# ISP_CBUFF register map
Vendor: Texas Instruments
Peripheral module from a debugger description file (folder omap36xx).
Registers are 32-bit, read-write, reset 0x0 unless marked. A register's access mark holds for its fields unless they carry their own. Offsets are as the file gives them; lines under a group give offsets from that group; [hi:lo] are bit positions; {n}, {i} and the like mark numbered series; 'fields as' and 'values as' point back to an identical list; <NAME> marks a mode.

## ISP_CBUFF
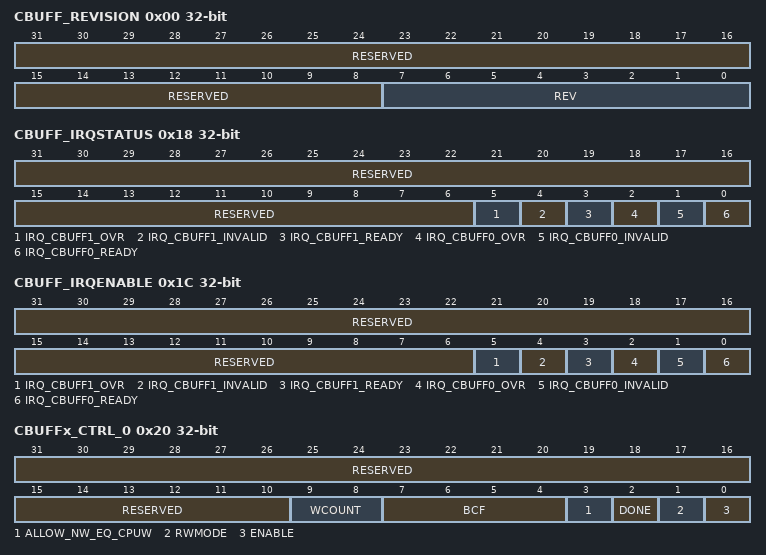
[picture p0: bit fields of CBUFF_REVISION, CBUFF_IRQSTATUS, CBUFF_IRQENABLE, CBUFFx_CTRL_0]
0x00 CBUFF_REVISION ro (reset mask 0xFFFFFF00) — This register contains the IP revision code
  [31:8] RESERVED — Write 0s for future compatibility. Read returns 0.
  [7:0] REV — IP revision[7:4] Major revision . [3:0] Minor revision .
0x10 CBUFF_SYSCONFIG — This register allows controlling various parameters of the Interconnect interface.
  [31:0] RESERVED — Write 0s for future compatibility. Reads return zero.
0x14 CBUFF_SYSSTATUS ro — The register provides status information about the module, excluding the interrupt status information
0x18 CBUFF_IRQSTATUS access not given — The interrupt status register regroups all the status of the module internal events that can generate an interrupt.
  [31:6] RESERVED rw — Write 0s for future compatibility. Reads return zero.
  [5] IRQ_CBUFF1_OVR — Buffer overflow event. (access R/W/1toClr)
    0=No done interrupt pending (r); Status unchanged (w); 1=Done interrupt pending (r); Status bit cleared (w)
  [4] IRQ_CBUFF1_INVALID — Invalid access. (access R/W/1toClr)
    values as IRQ_CBUFF1_OVR
  [3] IRQ_CBUFF1_READY — The CPUW1 physical buffer is ready to be accessed by the CPU. (access R/W/1toClr)
    values as IRQ_CBUFF1_OVR
  [2] IRQ_CBUFF0_OVR — Buffer overflow event. (access R/W/1toClr)
    values as IRQ_CBUFF1_OVR
  [1] IRQ_CBUFF0_INVALID — Invalid access. (access R/W/1toClr)
    0=No YUV buffer done interrupt pending (r); Status unchanged (w); 1=YUV buffer done interrupt pending (r); Status bit cleared (w)
  [0] IRQ_CBUFF0_READY — The CPUW0 physical buffer is ready to be accessed by the CPU. (access R/W/1toClr)
    values as IRQ_CBUFF1_OVR
0x1C CBUFF_IRQENABLE — The interrupt enable register allows to enable/disable the module internal sources of interrupt, on an event-by-event basis.
  [31:6] RESERVED — Write 0s for future compatibility. Reads return zero.
  [5] IRQ_CBUFF1_OVR — Buffer overflow event.
    0=interrupt is masked; 1=Interrupt is enabled
  [4] IRQ_CBUFF1_INVALID — Invalid access.
    0=interrupt is masked; 1=Interrupt is enabled
  [3] IRQ_CBUFF1_READY — The CPUW1 physical buffer is ready to be accessed by the CPU.
    0=interrupt is masked; 1=Interrupt is enabled
  [2] IRQ_CBUFF0_OVR — Buffer overflow event.
    0=interrupt is masked; 1=Interrupt is enabled
  [1] IRQ_CBUFF0_INVALID — Invalid access.
    0=interrupt is masked; 1=Interrupt is enabled
  [0] IRQ_CBUFF0_READY — The CPUW0 physical buffer is ready to be accessed by the CPU.
    0=interrupt is masked; 1=Interrupt is enabled
0x20 CBUFFx_CTRL_0 access per field — Circular buffer x control register
  [31:10] RESERVED rw — Write 0s for future compatibility.Reads returns 0.
  [9:8] WCOUNT rw — Window count
    0=2 windows; 1=4 windows; 2=8 windows; 3=16 windows
  [7:4] BCF rw — This register controls the bandwidth control feedback loop output.Functionality depends on subsystem integration.0: Control loop disabled. Data read from memory is free running.1-15: The control feedback loop signal is asserted when the window count available for ISP is below () the threshold.In other words at least (=) BCF windows are available for ISP access when this signal is released.
  [3] ALLOW_NW_EQ_CPUW rw — Allow NW=CPUW. Better buffer utilization when ISP does not use the next write window.
    0=When the CPUW and the NW pointers designate the same window and accesses are effectively performed to those windows an overflow event occurs.This happens when - the CPU has received an READY IRQ for that window indicating that it can be accessed and - the ISP performs an access to that window. ISP accesses are tracked based on OCPI activity.; 1=When the CPUW and the CW pointers designate the same window and accesses are effectively performed to those windows an overflow event occurs.This happens when - the CPU has received an READY IRQ for that window indicating that it can be accessed and - the ISP performs an access to that window. ISP accesses are tracked based on OCPI activity.
  [2] DONE wo — Write this bit to 1 to indicate the CPU has finished processing its physical buffer.This bit is automatically cleared by hardware, reads always return 0.
    0=No effect; 1=The CPU has completely processed the CPUW physical buffer
  [1] RWMODE rw — Selects read or write mode
    0=Write mode. HW writes and CPU reads the physical space. CPU accesses are out of CBUFF module's scope, therefore only writes are permitted between CBUFF0_START and CBUFF0_END.; 1=Read mode. HW reads and CPU writes the physical space. CPU accesses are out of CBUFF module's scope; therefore only reads are permitted between CBUFF0_START and CBUFF0_END.
  [0] ENABLE rw — Enable/disable
    0=Disables the circular buffer 0; this resets the internal state of circular buffer 0. All accesses received on OCPI are transmitted to OCPO without modification. Disabling the module takes effect immediately. It is SW responsibility to ensure that no more accesses to CBUFF0 are outstanding before disabling the module. Otherwise memory corruption may occur.; 1=Enable the circular buffer 0. All accesses between CBUFF0_START and CBUFF0_END are processed by the module.
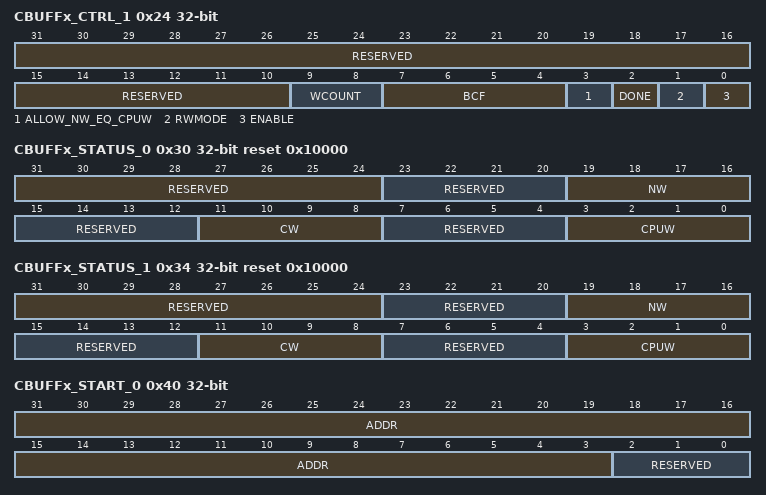
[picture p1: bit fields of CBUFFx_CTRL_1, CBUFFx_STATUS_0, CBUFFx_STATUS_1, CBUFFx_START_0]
0x24 CBUFFx_CTRL_1 access per field — Circular buffer x control register
  fields as CBUFFx_CTRL_0
0x30 CBUFFx_STATUS_0 ro reset 0x10000 — Threshold value used to check if the CW or NW windows are full.
  [31:24] RESERVED — Write 0s for future compatibility. Read returns 0.
  [23:20] RESERVED — Write 0s for future compatibility. Read returns 0.
  [19:16] NW — Next window number.Valid values depend on the CBUFF_CTRL.WCOUNT register.
  [15:12] RESERVED — Write 0s for future compatibility. Read returns 0.
  [11:8] CW — Current window number.Valid values depend on the CBUFF_CTRL.WCOUNT register.
  [7:4] RESERVED — Write 0s for future compatibility. Read returns 0.
  [3:0] CPUW — Current CPU window number.Valid values depend on the CBUFF_CTRL.WCOUNT register.
0x34 CBUFFx_STATUS_1 ro reset 0x10000 — Threshold value used to check if the CW or NW windows are full.
  fields as CBUFFx_STATUS_0
0x40 CBUFFx_START_0 — Start address of the virtual space managed by circular buffer x. Start address of the 1st physical buffer managed by circular buffer x.
  [31:3] ADDR — Address, in 64 bit words.
  [2:0] RESERVED — Write 0s for future compatibility.Reads returns 0.
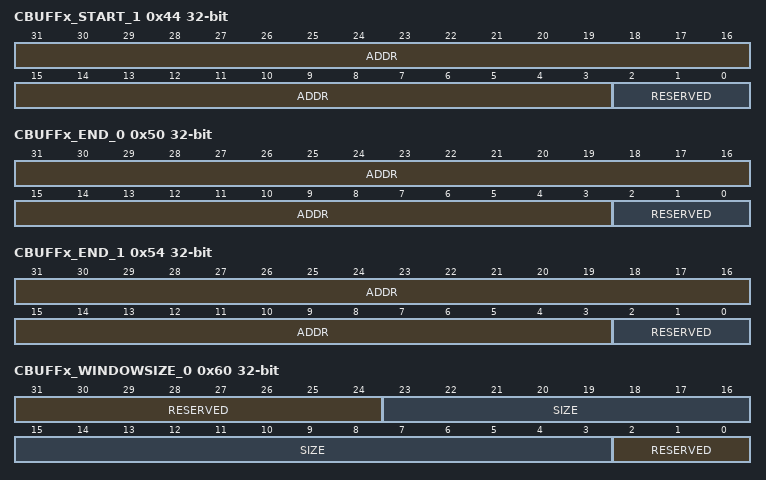
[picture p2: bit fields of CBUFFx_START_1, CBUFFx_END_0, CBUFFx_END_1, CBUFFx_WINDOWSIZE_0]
0x44 CBUFFx_START_1 — Start address of the virtual space managed by circular buffer x. Start address of the 1st physical buffer managed by circular buffer x.
  fields as CBUFFx_START_0
0x50 CBUFFx_END_0 — End address of the virtual space managed by circular buffer x.
  fields as CBUFFx_START_0
0x54 CBUFFx_END_1 — End address of the virtual space managed by circular buffer x.
  fields as CBUFFx_START_0
0x60 CBUFFx_WINDOWSIZE_0 — Defines the window size.
  [31:24] RESERVED — Write 0s for future compatibility.Reads returns 0.
  [23:3] SIZE — Size, in 64 bit words.
  [2:0] RESERVED — Write 0s for future compatibility.Reads returns 0.
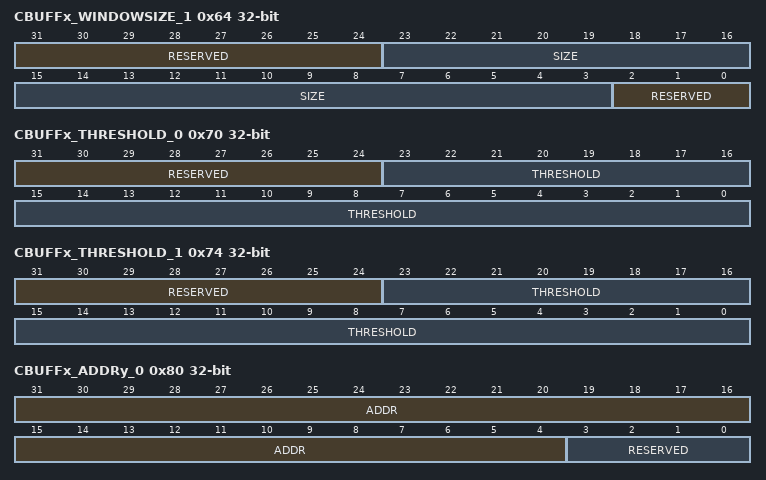
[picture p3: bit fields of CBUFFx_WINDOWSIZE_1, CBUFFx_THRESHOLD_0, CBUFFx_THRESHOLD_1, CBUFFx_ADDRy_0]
0x64 CBUFFx_WINDOWSIZE_1 — Defines the window size.
  fields as CBUFFx_WINDOWSIZE_0
0x70 CBUFFx_THRESHOLD_0 — Threshold value used to check if a write window is full.
  [31:24] RESERVED — Write 0s for future compatibility.Reads returns 0.
  [23:0] THRESHOLD — Threshold value, in bytes.
0x74 CBUFFx_THRESHOLD_1 — Threshold value used to check if a write window is full.
  fields as CBUFFx_THRESHOLD_0
0x80 CBUFFx_ADDRy_0 access per field — Start address of the physical buffer of the circular buffer context 0. This register only exists as RW for CBUFF 0. Fragmentation support is enabled for inly CBUFF0_ADDR0 through CBUFF0_ADDR15.
  [31:4] ADDR rw — Address, in 128 bit words.
  [3:0] RESERVED ro — Write 0s for future compatibility. Read returns 0.
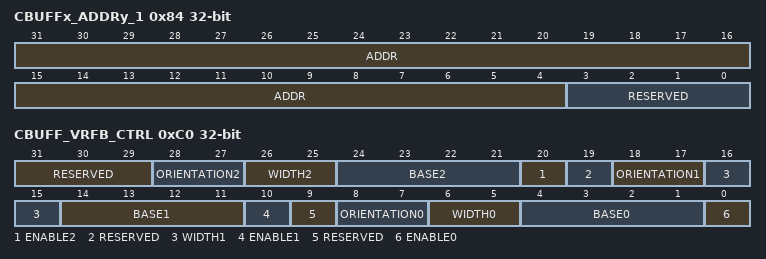
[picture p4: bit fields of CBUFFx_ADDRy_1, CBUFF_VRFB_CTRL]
0x84 CBUFFx_ADDRy_1 access per field — Start address of the physical buffer of the circular buffer context 0. This register only exists as RW for CBUFF 0. Fragmentation support is enabled for inly CBUFF0_ADDR0 through CBUFF0_ADDR15.
  fields as CBUFFx_ADDRy_0
0xC0 CBUFF_VRFB_CTRL access per field — VRFB context grouping control register
  [31:29] RESERVED ro — Write 0s for future compatibility. Read returns 0.
  [28:27] ORIENTATION2 rw — Orientation
    0=0 degrees; 1=90 degrees; 2=180 degrees; 3=270 degrees
  [26:25] WIDTH2 rw — Data width
    0=8 bits; 1=16 bits; 2=32 bits
  [24:21] BASE2 rw — Region being translated when translation is enabled. CBUFF_VRFB_CTRL.BASEx*256 Mega Bytes to CBUFF_VRFB_CTRL.BASEx+1)*256 Mega Bytes
  [20] ENABLE2 rw — Enable / disable VRFB context grouping.Sw shall not change this register when there's active traffic to the translated region
    0=Disabled; 1=Enabled
  [19] RESERVED ro — Write 0s for future compatibility. Read returns 0.
  [18:17] ORIENTATION1 rw — Orientation
    0=0 degrees; 1=90 degrees; 2=180 degrees; 3=270 degrees
  [16:15] WIDTH1 rw — Data width
    0=8 bits; 1=16 bits; 2=32 bits
  [14:11] BASE1 rw — Region being translated when translation is enabled. CBUFF_VRFB_CTRL.BASEx*256 Mega Bytes to CBUFF_VRFB_CTRL.BASEx+1)*256 Mega Bytes
  [10] ENABLE1 rw — Enable / disable VRFB context grouping.Sw shall not change this register when there's active traffic to the translated region
    0=Disabled; 1=Enabled
  [9] RESERVED ro — Write 0s for future compatibility. Read returns 0.
  [8:7] ORIENTATION0 rw — Orientation
    0=0 degrees; 1=90 degrees; 2=180 degrees; 3=270 degrees
  [6:5] WIDTH0 rw
    0=8 bits; 1=16 bits; 2=32 bits
  [4:1] BASE0 rw — Region being translated when translation is enabled. CBUFF_VRFB_CTRL.BASEx*256 Mega Bytes to CBUFF_VRFB_CTRL.BASEx+1)*256 Mega Bytes
  [0] ENABLE0 rw — Enable / disable VRFB context grouping.Sw shall not change this register when there's active traffic to the translated region
    0=Disabled; 1=Enabled
